# DSS0_DISPC_0_COMMON_S1 register map
Vendor: Texas Instruments
Peripheral module from a debugger description file (folder J721S2).
Registers are 32-bit, access not given, reset 0x0 unless marked. A register's access mark holds for its fields unless they carry their own. Offsets are as the file gives them; lines under a group give offsets from that group; [hi:lo] are bit positions; {n}, {i} and the like mark numbered series; 'fields as' and 'values as' point back to an identical list; <NAME> marks a mode.

## DSS0_DISPC_0_COMMON_S1
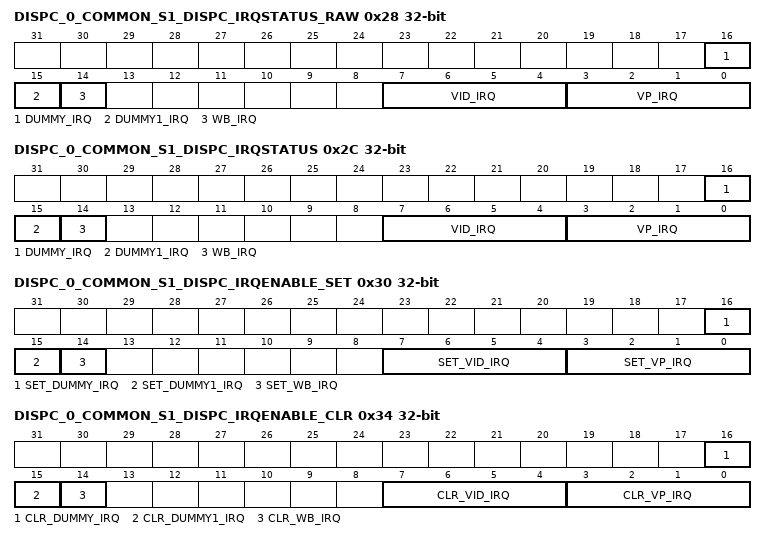
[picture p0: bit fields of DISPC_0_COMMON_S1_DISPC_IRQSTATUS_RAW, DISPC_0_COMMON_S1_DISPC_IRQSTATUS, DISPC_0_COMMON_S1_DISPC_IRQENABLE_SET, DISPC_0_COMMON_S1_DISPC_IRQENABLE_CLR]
0x28 DISPC_0_COMMON_S1_DISPC_IRQSTATUS_RAW — RAW Interrupt status. Raw status is set even if interrupt is not enabled. Write 1 to set the RAW status
  [16] DUMMY_IRQ — Dummy IRQ STATUS- Reserved for future use (access R/W1TS)
  [15] DUMMY1_IRQ — Dummy IRQ STATUS- Reserved for future use (access R/W1TS)
  [14] WB_IRQ — WB IRQ STATUS. Register indicates the WB pipeline interrupt events, if WB pipeline is present (access R/W1TS)
  [7:4] VID_IRQ — VID IRQ STATUS. Register indicates the Video pipeline[s] interrupt events. [0] -> VID1, [1] -> VIDL1, [2] -> VID2, [3] -> VIDL2 (access R/W1TS)
  [3:0] VP_IRQ — VP[3:0] IRQ STATUS. Register indicates the Video Port[s] interrupt events (access R/W1TS)
0x2C DISPC_0_COMMON_S1_DISPC_IRQSTATUS — Interrupt status. Enabled status, isn't set unless event is enabled. Write 1 to clear the status after interrupt has been serviced. RAW status also gets cleared, i.e. even if not enabled
  [16] DUMMY_IRQ — Dummy IRQ STATUS-Reserved for future use (access R/W1TC)
  [15] DUMMY1_IRQ — Dummy IRQ STATUS-Reserved for future use (access R/W1TC)
  [14] WB_IRQ — WB IRQ STATUS. Register indicates the WB pipeline interrupt events, if WB pipeline is present (access R/W1TC)
  [7:4] VID_IRQ — VID IRQ STATUS. Register indicates the Video pipeline[s] interrupt events. [0] -> VID1, [1] -> VIDL1, [2] -> VID2, [3] -> VIDL2 (access R/W1TC)
  [3:0] VP_IRQ — VP IRQ STATUS. Register indicates the Video Port[s] interrupt events (access R/W1TC)
0x30 DISPC_0_COMMON_S1_DISPC_IRQENABLE_SET — SET Interrupt enable. Write 1 to set interrupt enable. Readout equal to corresponding _CLR register
  [16] SET_DUMMY_IRQ — Dummy IRQ (access R/W1TS)
  [15] SET_DUMMY1_IRQ — Dummy IRQ (access R/W1TS)
  [14] SET_WB_IRQ — WB IRQ, if WB pipeline is present (access R/W1TS)
  [7:4] SET_VID_IRQ — VID IRQ. [0] -> VID1, [1] -> VIDL1, [2] -> VID2, [3] -> VIDL2 (access R/W1TS)
  [3:0] SET_VP_IRQ — VP IRQ (access R/W1TS)
0x34 DISPC_0_COMMON_S1_DISPC_IRQENABLE_CLR — CLR Interrupt enable. Write 1 to clear interrupt enable
  [16] CLR_DUMMY_IRQ — Dummy IRQ (access R/W1TC)
  [15] CLR_DUMMY1_IRQ — Dummy IRQ (access R/W1TC)
  [14] CLR_WB_IRQ — WB IRQ, if WB pipeline is present (access R/W1TC)
  [7:4] CLR_VID_IRQ — VID IRQ. [0] -> VID1, [1] -> VIDL1, [2] -> VID2, [3] -> VIDL2 (access R/W1TC)
  [3:0] CLR_VP_IRQ — VP IRQ (access R/W1TC)
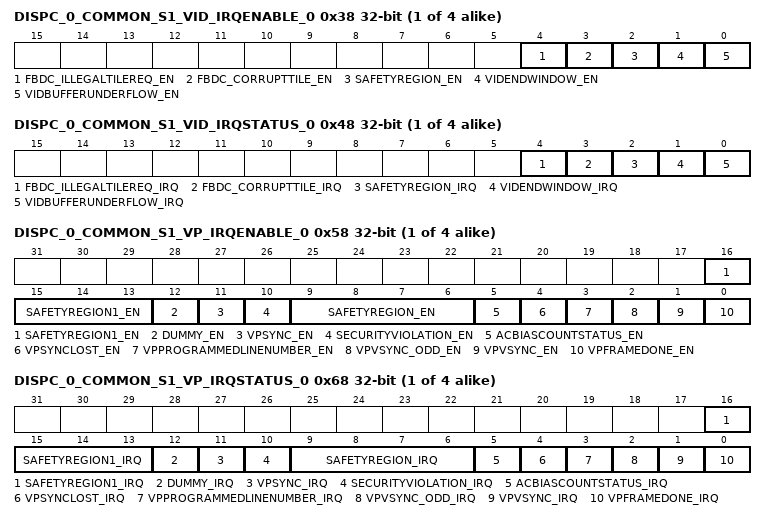
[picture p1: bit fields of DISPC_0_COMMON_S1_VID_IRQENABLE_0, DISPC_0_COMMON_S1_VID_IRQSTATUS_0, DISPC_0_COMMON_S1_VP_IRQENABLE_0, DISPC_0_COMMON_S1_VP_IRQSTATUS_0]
{0x38+4i} DISPC_0_COMMON_S1_VID_IRQENABLE_{i} rw (i=0..3) — This register allows to mask/unmask the VID internal sources of interrupt, on an event-by-event basis. [0] -> VID1, [1] -> VIDL1, [2] -> VID2, [3] -> VIDL2
  [4] FBDC_ILLEGALTILEREQ_EN — Safety Feature IRQ. This is raised when FrameFreeze is detected or data mismatch occurs within the safety region
  [3] FBDC_CORRUPTTILE_EN — Safety Feature IRQ. This is raised when FrameFreeze is detected or data mismatch occurs within the safety region
  [2] SAFETYREGION_EN — Safety Feature IRQ. This is raised when FrameFreeze is detected or data mismatch occurs within the safety region
  [1] VIDENDWINDOW_EN — Video End Window. This is raised by the DMA engine when the full video data has been sent to the pipeline
  [0] VIDBUFFERUNDERFLOW_EN — Video DMA Buffer Underflow. This is raised when the DMA buffer does not have the data requested by the Video pipeline
{0x48+4i} DISPC_0_COMMON_S1_VID_IRQSTATUS_{i} (i=0..3) — This register groups all the status of the VID internal events that generate an interrupt. Write 1 to a clear a bit field. [0] -> VID1, [1] -> VIDL1, [2] -> VID2, [3] -> VIDL2
  [4] FBDC_ILLEGALTILEREQ_IRQ — Safety Feature IRQ. This is raised when FrameFreeze is detected or data mismatch occurs within the safety region (access R/W1TC)
  [3] FBDC_CORRUPTTILE_IRQ — Safety Feature IRQ. This is raised when FrameFreeze is detected or data mismatch occurs within the safety region (access R/W1TC)
  [2] SAFETYREGION_IRQ — Safety Feature IRQ. This is raised when FrameFreeze is detected or data mismatch occurs within the safety region (access R/W1TC)
  [1] VIDENDWINDOW_IRQ — Video End Window. This is raised by the DMA engine when the full video data has been sent to the pipeline (access R/W1TC)
  [0] VIDBUFFERUNDERFLOW_IRQ — Video DMA Buffer Underflow. This is raised when the DMA buffer does not have the data requested by the Video pipeline (access R/W1TC)
{0x58+4i} DISPC_0_COMMON_S1_VP_IRQENABLE_{i} rw (i=0..3) — This register allows to mask/unmask the VP_{i} internal sources of interrupt, on an event-by-event basis
  [16:13] SAFETYREGION1_EN — Safety Feature IRQ. This is raised when FrameFreeze is detected or data mismatch occurs within the safety region 4-7
  [12] DUMMY_EN — Dummy IRQ for future use
  [11] VPSYNC_EN — Go bit clear event
  [10] SECURITYVIOLATION_EN — Security Violation interrupt for OVR/VP. Non-secure OVR/VP connected to secure VID
  [9:6] SAFETYREGION_EN — Safety Feature IRQ. This is raised when FrameFreeze is detected or data mismatch occurs within the safety region 0-3
  [5] ACBIASCOUNTSTATUS_EN — AC BIAS transition counter has decremented to zero
  [4] VPSYNCLOST_EN — Synchronization Lost for Video Port
  [3] VPPROGRAMMEDLINENUMBER_EN — Programmed Line Number. It indicates that the scan of the display has reached the programmed user line number
  [2] VPVSYNC_ODD_EN — VSYNC for odd field from interlace mode only
  [1] VPVSYNC_EN — Vertical Synchronization for VP
  [0] VPFRAMEDONE_EN — Frame Done for Video Port. VP output has been disabled by user. All the data have been sent
{0x68+4i} DISPC_0_COMMON_S1_VP_IRQSTATUS_{i} (i=0..3) — This register groups all the status of the VP_{i} internal events that generate an interrupt. Write 1 to a given bit resets this bit
  [16:13] SAFETYREGION1_IRQ — Safety Feature IRQ. This is raised when FrameFreeze is detected or data mismatch occurs within the safety region 4-7 (access R/W1TC)
  [12] DUMMY_IRQ — Dummy IRQ for future use (access R/W1TC)
  [11] VPSYNC_IRQ — Go bit clear event (access R/W1TC)
  [10] SECURITYVIOLATION_IRQ — Security Violation IRQ. Non-secure OVR/VP connected to secure VID (access R/W1TC)
  [9:6] SAFETYREGION_IRQ — Safety Feature IRQ. This is raised when FrameFreeze is detected or data mismatch occurs within the safety region 0-3 (access R/W1TC)
  [5] ACBIASCOUNTSTATUS_IRQ — AC BIAS transition counter has decremented to zero (access R/W1TC)
  [4] VPSYNCLOST_IRQ — Synchronization Lost on VP output. The required data are not output at the correct time due to too short blanking periods or stall of at least one pipelines associated with VP output (access R/W1TC)
  [3] VPPROGRAMMEDLINENUMBER_IRQ — Programmed Line Number. It indicates that the scan of the display has reached the programmed user line number (access R/W1TC)
  [2] VPVSYNC_ODD_IRQ — VSYNC for odd field. For interlace mode only (access R/W1TC)
  [1] VPVSYNC_IRQ — Vertical Synchronization for VP output. It is used as VSYNC_EVEN in case of interlace mode (access R/W1TC)
  [0] VPFRAMEDONE_IRQ — Frame Done for VP. VP output has been disabled by user All the data have been sent (access R/W1TC)
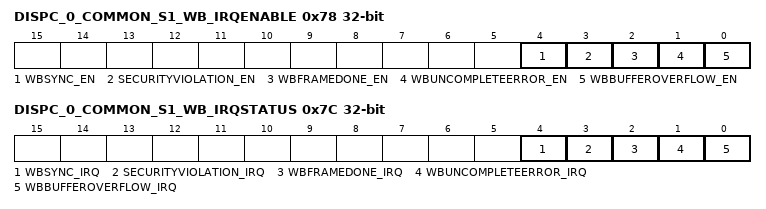
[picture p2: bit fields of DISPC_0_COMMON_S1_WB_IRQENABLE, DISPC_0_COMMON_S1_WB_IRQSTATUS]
0x78 DISPC_0_COMMON_S1_WB_IRQENABLE rw — This register allows to mask/unmask the WB internal sources of interrupt, if WB pipeline is present, on an event-by-event basis
  [4] WBSYNC_EN — Write-back sync IRQ. Configuration copied from shadow to work for WB for next frame
  [3] SECURITYVIOLATION_EN — Security Violation IRQ. Non-secure WB connected to a secure VID/OVR
  [2] WBFRAMEDONE_EN — Write-back Frame Done
  [1] WBUNCOMPLETEERROR_EN — The write back buffer has been flushed before been fully drained. Can only occur in WB Capture Mode use-case
  [0] WBBUFFEROVERFLOW_EN — Write-back DMA Buffer Overflow. Can only occur in WB Capture Mode use-case
0x7C DISPC_0_COMMON_S1_WB_IRQSTATUS — This register groups all the status of the WB internal events that generate an interrupt, if WB pipeline is present. Write 1 to a given bit resets this bit
  [4] WBSYNC_IRQ — Write-back sync IRQ. Configuration copied from shadow to work for WB for next frame (access R/W1TC)
  [3] SECURITYVIOLATION_IRQ — Security Violation IRQ. Non-secure WB connected to a secure VID/OVR (access R/W1TC)
  [2] WBFRAMEDONE_IRQ — Write-back Frame Done (access R/W1TC)
  [1] WBUNCOMPLETEERROR_IRQ — Write back DMA buffer is flushed before been completely drained. Can only occur in WB Capture Mode use-case (access R/W1TC)
  [0] WBBUFFEROVERFLOW_IRQ — Write-back DMA Buffer Overflow The DMA buffer is full (access R/W1TC)
0x80 DISPC_0_COMMON_S1_DISPC_IRQ_EOI_FUNC wo — End-Of-Interrupt register for FUNC interrupts, to be used if pulse interrupts are used
  [0] EOI — Write 1 to acknowledge a pulse IRQ
0x84 DISPC_0_COMMON_S1_DISPC_IRQ_EOI_SAFETY wo — End-Of-Interrupt register for SAFETY interrupts, to be used if pulse interrupts are used
  [0] EOI — Write 1 to acknowledge a pulse IRQ
0x88 DISPC_0_COMMON_S1_DISPC_IRQ_EOI_SECURITY wo — End-Of-Interrupt register for SECURITY interrupts, to be used if pulse interrupts are used
  [0] EOI — Write 1 to acknowledge a pulse IRQ
